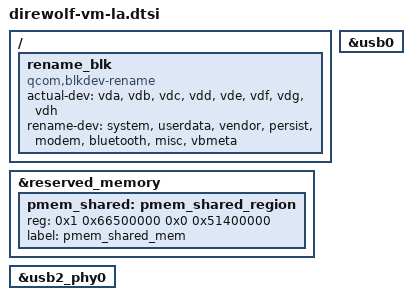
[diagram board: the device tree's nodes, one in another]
&reserved_memory {
	pmem_shared: pmem_shared_region {
		reg = <0x1 0x66500000 0x0 0x51400000>;
		label = "pmem_shared_mem";
	};
};

&usb0 {
	status = "okay";
};

&usb2_phy0 {
	status = "okay";
};

/ {
	rename_blk: rename_blk {
		compatible = "qcom,blkdev-rename";
		actual-dev = "vda", "vdb", "vdc",
				"vdd", "vde", "vdf",
				"vdg", "vdh";
		rename-dev = "system", "userdata", "vendor",
				"persist", "modem", "bluetooth",
				"misc", "vbmeta";
	};
};
